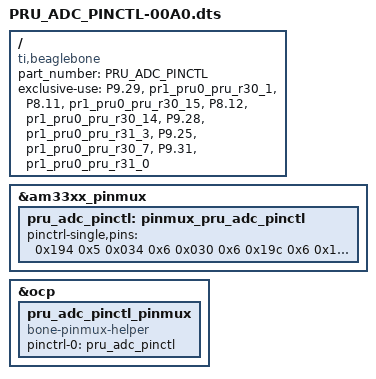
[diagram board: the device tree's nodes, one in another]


/dts-v1/;
/plugin/;

/{
    compatible = "ti,beaglebone", "ti,beaglebone-black";
    part_number = "PRU_ADC_PINCTL";

    exclusive-use =
        "P9.29",
        "pr1_pru0_pru_r30_1",
        "P8.11",
        "pr1_pru0_pru_r30_15",
        "P8.12",
        "pr1_pru0_pru_r30_14",
        "P9.28",
        "pr1_pru0_pru_r31_3",
        "P9.25",
        "pr1_pru0_pru_r30_7",
        "P9.31",
        "pr1_pru0_pru_r31_0";



    fragment@0 {
        target = <&am33xx_pinmux>;
        __overlay__ {
            pru_adc_pinctl: pinmux_pru_adc_pinctl {
                pinctrl-single,pins = <
                        0x194 0x5
                        0x034 0x6
                        0x030 0x6
                        0x19c 0x6
                        0x1ac 0x5
                        0x190 0x6
                >;
            };
        };
    };

    fragment@1 {
        target = <&ocp>;
        __overlay__ {
            pru_adc_pinctl_pinmux {
                compatible = "bone-pinmux-helper";
                status = "okay";
                pinctrl-names = "default";
                pinctrl-0 = <&pru_adc_pinctl>;
            };
        };
    };
};
